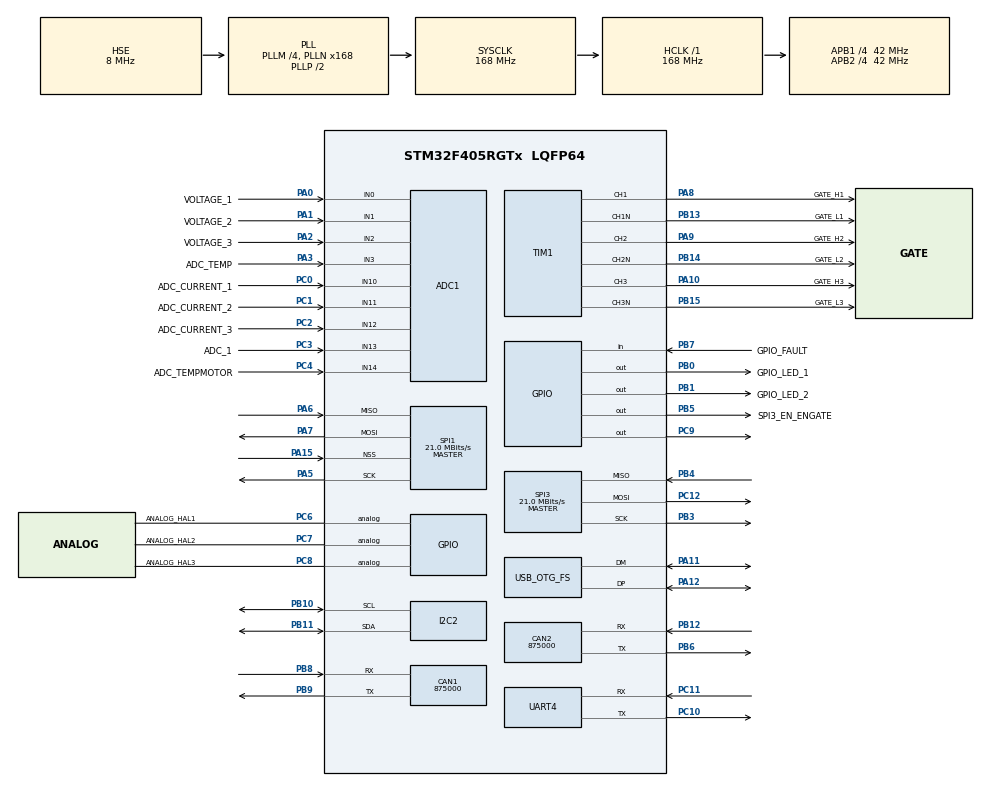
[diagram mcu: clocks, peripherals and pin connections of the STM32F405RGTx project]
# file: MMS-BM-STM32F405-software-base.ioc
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ADC1.Channel-0\#ChannelRegularConversion=ADC_CHANNEL_0
ADC1.NbrOfConversionFlag=1
ADC1.Rank-0\#ChannelRegularConversion=1
ADC1.SamplingTime-0\#ChannelRegularConversion=ADC_SAMPLETIME_3CYCLES
ADC1.master=1
CAN1.BS1=CAN_BS1_1TQ
CAN1.BS2=CAN_BS2_1TQ
CAN1.CalculateBaudRate=875000
CAN1.CalculateTimeBit=1142
CAN1.CalculateTimeQuantum=380.95238095238096
CAN2.BS1=CAN_BS1_1TQ
CAN2.BS2=CAN_BS2_1TQ
CAN2.CalculateBaudRate=875000
CAN2.CalculateTimeBit=1142
CAN2.CalculateTimeQuantum=380.95238095238096
FREERTOS.INCLUDE_vTaskCleanUpResources=1
FREERTOS.Tasks01=defaultTask,24,256,StartDefaultTask,Default,NULL,Dynamic,NULL,NULL
FREERTOS.configENABLE_FPU=1
FREERTOS.configMINIMAL_STACK_SIZE=256
FREERTOS.configQUEUE_REGISTRY_SIZE=32
FREERTOS.configTOTAL_HEAP_SIZE=100000
FREERTOS.configUSE_NEWLIB_REENTRANT=1
Mcu.Family=STM32F4
Mcu.Name=STM32F405RGTx
Mcu.Package=LQFP64
NVIC.OTG_FS_IRQn=true\:5\:0\:false\:false\:true\:true\:false\:true\:true
NVIC.PriorityGroup=NVIC_PRIORITYGROUP_4
NVIC.TIM6_DAC_IRQn=true\:5\:0\:false\:false\:true\:true\:true\:true\:true
NVIC.TIM7_IRQn=true\:15\:0\:false\:false\:true\:false\:false\:true\:true
NVIC.TimeBase=TIM7_IRQn
NVIC.TimeBaseIP=TIM7
PA0-WKUP.GPIO_Label=VOLTAGE_1
PA0-WKUP.Signal=ADCx_IN0
PA1.GPIO_Label=VOLTAGE_2
PA1.Signal=ADCx_IN1
PA10.GPIO_Label=GATE_H3
PA10.Signal=S_TIM1_CH3
PA11.Mode=Device_Only
PA11.Signal=USB_OTG_FS_DM
PA12.Mode=Device_Only
PA12.Signal=USB_OTG_FS_DP
PA13.Mode=Serial_Wire
PA13.Signal=SYS_JTMS-SWDIO
PA14.Mode=Serial_Wire
PA14.Signal=SYS_JTCK-SWCLK
PA15.Mode=NSS_Signal_Hard_Input
PA15.Signal=SPI1_NSS
PA2.GPIO_Label=VOLTAGE_3
PA2.Signal=ADCx_IN2
PA3.GPIO_Label=ADC_TEMP
PA3.Signal=ADCx_IN3
PA5.Mode=Full_Duplex_Master
PA5.Signal=SPI1_SCK
PA6.Mode=Full_Duplex_Master
PA6.Signal=SPI1_MISO
PA7.Mode=Full_Duplex_Master
PA7.Signal=SPI1_MOSI
PA8.GPIO_Label=GATE_H1
PA8.Signal=S_TIM1_CH1
PA9.GPIO_Label=GATE_H2
PA9.Signal=S_TIM1_CH2
PB0.GPIO_Label=GPIO_LED_1
PB0.Signal=GPIO_Output
PB1.GPIO_Label=GPIO_LED_2
PB1.Signal=GPIO_Output
PB10.Mode=I2C
PB10.Signal=I2C2_SCL
PB11.Mode=I2C
PB11.Signal=I2C2_SDA
PB12.Mode=CAN_Activate
PB12.Signal=CAN2_RX
PB13.GPIO_Label=GATE_L1
PB13.Mode=PWM Generation1 CH1 CH1N
PB13.Signal=TIM1_CH1N
PB14.GPIO_Label=GATE_L2
PB14.Mode=PWM Generation2 CH2 CH2N
PB14.Signal=TIM1_CH2N
PB15.GPIO_Label=GATE_L3
PB15.Mode=PWM Generation3 CH3 CH3N
PB15.Signal=TIM1_CH3N
PB3.Mode=Full_Duplex_Master
PB3.Signal=SPI3_SCK
PB4.Mode=Full_Duplex_Master
PB4.Signal=SPI3_MISO
PB5.GPIO_Label=SPI3_EN_ENGATE
PB5.Signal=GPIO_Output
PB6.Mode=CAN_Activate
PB6.Signal=CAN2_TX
PB7.GPIO_Label=GPIO_FAULT
PB7.Signal=GPIO_Input
PB8.Mode=CAN_Activate
PB8.Signal=CAN1_RX
PB9.Mode=CAN_Activate
PB9.Signal=CAN1_TX
PC0.GPIO_Label=ADC_CURRENT_1
PC0.Signal=ADCx_IN10
PC1.GPIO_Label=ADC_CURRENT_2
PC1.Signal=ADCx_IN11
PC10.Mode=Asynchronous
PC10.Signal=UART4_TX
PC11.Mode=Asynchronous
PC11.Signal=UART4_RX
PC12.Mode=Full_Duplex_Master
PC12.Signal=SPI3_MOSI
PC14-OSC32_IN.Mode=LSE-External-Oscillator
PC14-OSC32_IN.Signal=RCC_OSC32_IN
PC15-OSC32_OUT.Mode=LSE-External-Oscillator
PC15-OSC32_OUT.Signal=RCC_OSC32_OUT
PC2.GPIO_Label=ADC_CURRENT_3
PC2.Signal=ADCx_IN12
PC3.GPIO_Label=ADC_1
PC3.Signal=ADCx_IN13
PC4.GPIO_Label=ADC_TEMPMOTOR
PC4.Signal=ADCx_IN14
PC6.GPIO_Label=ANALOG_HAL1
PC6.Signal=GPIO_Analog
PC7.GPIO_Label=ANALOG_HAL2
PC7.Signal=GPIO_Analog
PC8.GPIO_Label=ANALOG_HAL3
PC8.Signal=GPIO_Analog
PC9.Signal=GPIO_Output
PH0-OSC_IN.Mode=HSE-External-Oscillator
PH0-OSC_IN.Signal=RCC_OSC_IN
PH1-OSC_OUT.Mode=HSE-External-Oscillator
PH1-OSC_OUT.Signal=RCC_OSC_OUT
ProjectManager.HeapSize=0x600
ProjectManager.StackSize=0x400
ProjectManager.TargetToolchain=CMake
RCC.48MHZClocksFreq_Value=48000000
RCC.AHBFreq_Value=168000000
RCC.APB1CLKDivider=RCC_HCLK_DIV4
RCC.APB1Freq_Value=42000000
RCC.APB1TimFreq_Value=84000000
RCC.APB2CLKDivider=RCC_HCLK_DIV4
RCC.APB2Freq_Value=42000000
RCC.APB2TimFreq_Value=84000000
RCC.CortexFreq_Value=168000000
RCC.HCLKFreq_Value=168000000
RCC.HSE_VALUE=8000000
RCC.HSI_VALUE=16000000
RCC.PLLM=4
RCC.PLLN=168
RCC.PLLQ=7
RCC.SYSCLKFreq_VALUE=168000000
RCC.SYSCLKSource=RCC_SYSCLKSOURCE_PLLCLK
RCC.VCOOutputFreq_Value=336000000
SH.ADCx_IN0.0=ADC1_IN0,IN0
SH.ADCx_IN1.0=ADC1_IN1,IN1
SH.ADCx_IN10.0=ADC1_IN10,IN10
SH.ADCx_IN11.0=ADC1_IN11,IN11
SH.ADCx_IN12.0=ADC1_IN12,IN12
SH.ADCx_IN13.0=ADC1_IN13,IN13
SH.ADCx_IN14.0=ADC1_IN14,IN14
SH.ADCx_IN2.0=ADC1_IN2,IN2
SH.ADCx_IN3.0=ADC1_IN3,IN3
SH.S_TIM1_CH1.0=TIM1_CH1,PWM Generation1 CH1 CH1N
SH.S_TIM1_CH2.0=TIM1_CH2,PWM Generation2 CH2 CH2N
SH.S_TIM1_CH3.0=TIM1_CH3,PWM Generation3 CH3 CH3N
SPI1.BaudRatePrescaler=SPI_BAUDRATEPRESCALER_2
SPI1.CalculateBaudRate=21.0 MBits/s
SPI1.Direction=SPI_DIRECTION_2LINES
SPI1.Mode=SPI_MODE_MASTER
SPI1.VirtualNSS=VM_NSSHARD
SPI1.VirtualType=VM_MASTER
SPI3.BaudRatePrescaler=SPI_BAUDRATEPRESCALER_2
SPI3.CalculateBaudRate=21.0 MBits/s
SPI3.Direction=SPI_DIRECTION_2LINES
SPI3.Mode=SPI_MODE_MASTER
SPI3.VirtualType=VM_MASTER
TIM1.Channel-PWM\ Generation1\ CH1\ CH1N=TIM_CHANNEL_1
TIM1.Channel-PWM\ Generation2\ CH2\ CH2N=TIM_CHANNEL_2
TIM1.Channel-PWM\ Generation3\ CH3\ CH3N=TIM_CHANNEL_3
TIM6.AutoReloadPreload=TIM_AUTORELOAD_PRELOAD_ENABLE
TIM6.Period=999
TIM6.Prescaler=168
UART4.VirtualMode=Asynchronous
USB_DEVICE.CLASS_NAME_FS=CDC
USB_DEVICE.VirtualMode-CDC_FS=Cdc
USB_DEVICE.VirtualModeFS=Cdc_FS
USB_OTG_FS.VirtualMode=Device_Only
VP_FREERTOS_VS_CMSIS_V2.Mode=CMSIS_V2
VP_RNG_VS_RNG.Mode=RNG_Activate
VP_SYS_VS_tim7.Mode=TIM7
VP_TIM6_VS_ClockSourceINT.Mode=Enable_Timer
VP_USB_DEVICE_VS_USB_DEVICE_CDC_FS.Mode=CDC_FS
board=custom

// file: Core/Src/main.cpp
/* USER CODE BEGIN Header */
/**
  ******************************************************************************
  * @file           : main.c
  * @brief          : Main program body
  ******************************************************************************
  * @attention
  *
  * Copyright (c) 2025 STMicroelectronics.
  * All rights reserved.
  *
  * This software is licensed under terms that can be found in the LICENSE file
  * in the root directory of this software component.
  * If no LICENSE file comes with this software, it is provided AS-IS.
  *
  ******************************************************************************
  */
/* USER CODE END Header */
#include "main.h"
#include "cmsis_os.h"
#include "usb_device.h"

/* USER CODE BEGIN Includes */
#include "main_prog.hpp"

/* USER CODE END Includes */

ADC_HandleTypeDef hadc1;

CAN_HandleTypeDef hcan1;
CAN_HandleTypeDef hcan2;

I2C_HandleTypeDef hi2c2;

RNG_HandleTypeDef hrng;

SPI_HandleTypeDef hspi1;
SPI_HandleTypeDef hspi3;

TIM_HandleTypeDef htim1;
TIM_HandleTypeDef htim6;

UART_HandleTypeDef huart4;

/* Definitions for defaultTask */
osThreadId_t defaultTaskHandle;
const osThreadAttr_t defaultTask_attributes = {
  .name = "defaultTask",
  .stack_size = 256 * 4,
  .priority = (osPriority_t) osPriorityNormal,
};

void SystemClock_Config(void);
static void MX_GPIO_Init(void);
static void MX_ADC1_Init(void);
static void MX_CAN1_Init(void);
static void MX_CAN2_Init(void);
static void MX_I2C2_Init(void);
static void MX_SPI1_Init(void);
static void MX_SPI3_Init(void);
static void MX_TIM1_Init(void);
static void MX_UART4_Init(void);
static void MX_RNG_Init(void);
static void MX_TIM6_Init(void);
void StartDefaultTask(void *argument);

int main(void)
{

  /* MCU Configuration--------------------------------------------------------*/

  /* Reset of all peripherals, Initializes the Flash interface and the Systick. */
  HAL_Init();

  /* Configure the system clock */
  SystemClock_Config();

  /* Initialize all configured peripherals */
  MX_GPIO_Init();
  MX_ADC1_Init();
  MX_CAN1_Init();
  MX_CAN2_Init();
  MX_I2C2_Init();
  MX_SPI1_Init();
  MX_SPI3_Init();
  MX_TIM1_Init();
  MX_UART4_Init();
  MX_RNG_Init();
  MX_TIM6_Init();

  /* Init scheduler */
  osKernelInitialize();
main_prog();

  /* Create the thread(s) */
  /* creation of defaultTask */
  defaultTaskHandle = osThreadNew(StartDefaultTask, NULL, &defaultTask_attributes);

  /* Start scheduler */
  osKernelStart();

  /* We should never get here as control is now taken by the scheduler */

  /* Infinite loop */
  while (1)
  {

  }
}

void SystemClock_Config(void)
{
  RCC_OscInitTypeDef RCC_OscInitStruct = {0};
  RCC_ClkInitTypeDef RCC_ClkInitStruct = {0};

  /** Configure the main internal regulator output voltage
  */
  __HAL_RCC_PWR_CLK_ENABLE();
  __HAL_PWR_VOLTAGESCALING_CONFIG(PWR_REGULATOR_VOLTAGE_SCALE1);

  /** Initializes the RCC Oscillators according to the specified parameters
  * in the RCC_OscInitTypeDef structure.
  */
  RCC_OscInitStruct.OscillatorType = RCC_OSCILLATORTYPE_HSE;
  RCC_OscInitStruct.HSEState = RCC_HSE_ON;
  RCC_OscInitStruct.PLL.PLLState = RCC_PLL_ON;
  RCC_OscInitStruct.PLL.PLLSource = RCC_PLLSOURCE_HSE;
  RCC_OscInitStruct.PLL.PLLM = 4;
  RCC_OscInitStruct.PLL.PLLN = 168;
  RCC_OscInitStruct.PLL.PLLP = RCC_PLLP_DIV2;
  RCC_OscInitStruct.PLL.PLLQ = 7;
  if (HAL_RCC_OscConfig(&RCC_OscInitStruct) != HAL_OK)
  {
    Error_Handler();
  }

  /** Initializes the CPU, AHB and APB buses clocks
  */
  RCC_ClkInitStruct.ClockType = RCC_CLOCKTYPE_HCLK|RCC_CLOCKTYPE_SYSCLK
                              |RCC_CLOCKTYPE_PCLK1|RCC_CLOCKTYPE_PCLK2;
  RCC_ClkInitStruct.SYSCLKSource = RCC_SYSCLKSOURCE_PLLCLK;
  RCC_ClkInitStruct.AHBCLKDivider = RCC_SYSCLK_DIV1;
  RCC_ClkInitStruct.APB1CLKDivider = RCC_HCLK_DIV4;
  RCC_ClkInitStruct.APB2CLKDivider = RCC_HCLK_DIV4;

  if (HAL_RCC_ClockConfig(&RCC_ClkInitStruct, FLASH_LATENCY_5) != HAL_OK)
  {
    Error_Handler();
  }
}

static void MX_ADC1_Init(void)
{

  ADC_ChannelConfTypeDef sConfig = {0};

  /** Configure the global features of the ADC (Clock, Resolution, Data Alignment and number of conversion)
  */
  hadc1.Instance = ADC1;
  hadc1.Init.ClockPrescaler = ADC_CLOCK_SYNC_PCLK_DIV2;
  hadc1.Init.Resolution = ADC_RESOLUTION_12B;
  hadc1.Init.ScanConvMode = DISABLE;
  hadc1.Init.ContinuousConvMode = DISABLE;
  hadc1.Init.DiscontinuousConvMode = DISABLE;
  hadc1.Init.ExternalTrigConvEdge = ADC_EXTERNALTRIGCONVEDGE_NONE;
  hadc1.Init.ExternalTrigConv = ADC_SOFTWARE_START;
  hadc1.Init.DataAlign = ADC_DATAALIGN_RIGHT;
  hadc1.Init.NbrOfConversion = 1;
  hadc1.Init.DMAContinuousRequests = DISABLE;
  hadc1.Init.EOCSelection = ADC_EOC_SINGLE_CONV;
  if (HAL_ADC_Init(&hadc1) != HAL_OK)
  {
    Error_Handler();
  }

  /** Configure for the selected ADC regular channel its corresponding rank in the sequencer and its sample time.
  */
  sConfig.Channel = ADC_CHANNEL_0;
  sConfig.Rank = 1;
  sConfig.SamplingTime = ADC_SAMPLETIME_3CYCLES;
  if (HAL_ADC_ConfigChannel(&hadc1, &sConfig) != HAL_OK)
  {
    Error_Handler();
  }

}

static void MX_CAN1_Init(void)
{

  hcan1.Instance = CAN1;
  hcan1.Init.Prescaler = 16;
  hcan1.Init.Mode = CAN_MODE_NORMAL;
  hcan1.Init.SyncJumpWidth = CAN_SJW_1TQ;
  hcan1.Init.TimeSeg1 = CAN_BS1_1TQ;
  hcan1.Init.TimeSeg2 = CAN_BS2_1TQ;
  hcan1.Init.TimeTriggeredMode = DISABLE;
  hcan1.Init.AutoBusOff = DISABLE;
  hcan1.Init.AutoWakeUp = DISABLE;
  hcan1.Init.AutoRetransmission = DISABLE;
  hcan1.Init.ReceiveFifoLocked = DISABLE;
  hcan1.Init.TransmitFifoPriority = DISABLE;
  if (HAL_CAN_Init(&hcan1) != HAL_OK)
  {
    Error_Handler();
  }

}

static void MX_CAN2_Init(void)
{

  hcan2.Instance = CAN2;
  hcan2.Init.Prescaler = 16;
  hcan2.Init.Mode = CAN_MODE_NORMAL;
  hcan2.Init.SyncJumpWidth = CAN_SJW_1TQ;
  hcan2.Init.TimeSeg1 = CAN_BS1_1TQ;
  hcan2.Init.TimeSeg2 = CAN_BS2_1TQ;
  hcan2.Init.TimeTriggeredMode = DISABLE;
  hcan2.Init.AutoBusOff = DISABLE;
  hcan2.Init.AutoWakeUp = DISABLE;
  hcan2.Init.AutoRetransmission = DISABLE;
  hcan2.Init.ReceiveFifoLocked = DISABLE;
  hcan2.Init.TransmitFifoPriority = DISABLE;
  if (HAL_CAN_Init(&hcan2) != HAL_OK)
  {
    Error_Handler();
  }

}

static void MX_I2C2_Init(void)
{

  hi2c2.Instance = I2C2;
  hi2c2.Init.ClockSpeed = 100000;
  hi2c2.Init.DutyCycle = I2C_DUTYCYCLE_2;
  hi2c2.Init.OwnAddress1 = 0;
  hi2c2.Init.AddressingMode = I2C_ADDRESSINGMODE_7BIT;
  hi2c2.Init.DualAddressMode = I2C_DUALADDRESS_DISABLE;
  hi2c2.Init.OwnAddress2 = 0;
  hi2c2.Init.GeneralCallMode = I2C_GENERALCALL_DISABLE;
  hi2c2.Init.NoStretchMode = I2C_NOSTRETCH_DISABLE;
  if (HAL_I2C_Init(&hi2c2) != HAL_OK)
  {
    Error_Handler();
  }

}

static void MX_RNG_Init(void)
{

  hrng.Instance = RNG;
  if (HAL_RNG_Init(&hrng) != HAL_OK)
  {
    Error_Handler();
  }

}

static void MX_SPI1_Init(void)
{

  /* SPI1 parameter configuration*/
  hspi1.Instance = SPI1;
  hspi1.Init.Mode = SPI_MODE_MASTER;
  hspi1.Init.Direction = SPI_DIRECTION_2LINES;
  hspi1.Init.DataSize = SPI_DATASIZE_8BIT;
  hspi1.Init.CLKPolarity = SPI_POLARITY_LOW;
  hspi1.Init.CLKPhase = SPI_PHASE_1EDGE;
  hspi1.Init.NSS = SPI_NSS_HARD_INPUT;
  hspi1.Init.BaudRatePrescaler = SPI_BAUDRATEPRESCALER_2;
  hspi1.Init.FirstBit = SPI_FIRSTBIT_MSB;
  hspi1.Init.TIMode = SPI_TIMODE_DISABLE;
  hspi1.Init.CRCCalculation = SPI_CRCCALCULATION_DISABLE;
  hspi1.Init.CRCPolynomial = 10;
  if (HAL_SPI_Init(&hspi1) != HAL_OK)
  {
    Error_Handler();
  }

}

static void MX_SPI3_Init(void)
{

  /* SPI3 parameter configuration*/
  hspi3.Instance = SPI3;
  hspi3.Init.Mode = SPI_MODE_MASTER;
  hspi3.Init.Direction = SPI_DIRECTION_2LINES;
  hspi3.Init.DataSize = SPI_DATASIZE_8BIT;
  hspi3.Init.CLKPolarity = SPI_POLARITY_LOW;
  hspi3.Init.CLKPhase = SPI_PHASE_1EDGE;
  hspi3.Init.NSS = SPI_NSS_SOFT;
  hspi3.Init.BaudRatePrescaler = SPI_BAUDRATEPRESCALER_2;
  hspi3.Init.FirstBit = SPI_FIRSTBIT_MSB;
  hspi3.Init.TIMode = SPI_TIMODE_DISABLE;
  hspi3.Init.CRCCalculation = SPI_CRCCALCULATION_DISABLE;
  hspi3.Init.CRCPolynomial = 10;
  if (HAL_SPI_Init(&hspi3) != HAL_OK)
  {
    Error_Handler();
  }

}

static void MX_TIM1_Init(void)
{

  TIM_MasterConfigTypeDef sMasterConfig = {0};
  TIM_OC_InitTypeDef sConfigOC = {0};
  TIM_BreakDeadTimeConfigTypeDef sBreakDeadTimeConfig = {0};

  htim1.Instance = TIM1;
  htim1.Init.Prescaler = 0;
  htim1.Init.CounterMode = TIM_COUNTERMODE_UP;
  htim1.Init.Period = 65535;
  htim1.Init.ClockDivision = TIM_CLOCKDIVISION_DIV1;
  htim1.Init.RepetitionCounter = 0;
  htim1.Init.AutoReloadPreload = TIM_AUTORELOAD_PRELOAD_DISABLE;
  if (HAL_TIM_PWM_Init(&htim1) != HAL_OK)
  {
    Error_Handler();
  }
  sMasterConfig.MasterOutputTrigger = TIM_TRGO_RESET;
  sMasterConfig.MasterSlaveMode = TIM_MASTERSLAVEMODE_DISABLE;
  if (HAL_TIMEx_MasterConfigSynchronization(&htim1, &sMasterConfig) != HAL_OK)
  {
    Error_Handler();
  }
  sConfigOC.OCMode = TIM_OCMODE_PWM1;
  sConfigOC.Pulse = 0;
  sConfigOC.OCPolarity = TIM_OCPOLARITY_HIGH;
  sConfigOC.OCNPolarity = TIM_OCNPOLARITY_HIGH;
  sConfigOC.OCFastMode = TIM_OCFAST_DISABLE;
  sConfigOC.OCIdleState = TIM_OCIDLESTATE_RESET;
  sConfigOC.OCNIdleState = TIM_OCNIDLESTATE_RESET;
  if (HAL_TIM_PWM_ConfigChannel(&htim1, &sConfigOC, TIM_CHANNEL_1) != HAL_OK)
  {
    Error_Handler();
  }
  if (HAL_TIM_PWM_ConfigChannel(&htim1, &sConfigOC, TIM_CHANNEL_2) != HAL_OK)
  {
    Error_Handler();
  }
  if (HAL_TIM_PWM_ConfigChannel(&htim1, &sConfigOC, TIM_CHANNEL_3) != HAL_OK)
  {
    Error_Handler();
  }
  sBreakDeadTimeConfig.OffStateRunMode = TIM_OSSR_DISABLE;
  sBreakDeadTimeConfig.OffStateIDLEMode = TIM_OSSI_DISABLE;
  sBreakDeadTimeConfig.LockLevel = TIM_LOCKLEVEL_OFF;
  sBreakDeadTimeConfig.DeadTime = 0;
  sBreakDeadTimeConfig.BreakState = TIM_BREAK_DISABLE;
  sBreakDeadTimeConfig.BreakPolarity = TIM_BREAKPOLARITY_HIGH;
  sBreakDeadTimeConfig.AutomaticOutput = TIM_AUTOMATICOUTPUT_DISABLE;
  if (HAL_TIMEx_ConfigBreakDeadTime(&htim1, &sBreakDeadTimeConfig) != HAL_OK)
  {
    Error_Handler();
  }
  HAL_TIM_MspPostInit(&htim1);

}

static void MX_TIM6_Init(void)
{

  TIM_MasterConfigTypeDef sMasterConfig = {0};

  htim6.Instance = TIM6;
  htim6.Init.Prescaler = 168;
  htim6.Init.CounterMode = TIM_COUNTERMODE_UP;
  htim6.Init.Period = 999;
  htim6.Init.AutoReloadPreload = TIM_AUTORELOAD_PRELOAD_ENABLE;
  if (HAL_TIM_Base_Init(&htim6) != HAL_OK)
  {
    Error_Handler();
  }
  sMasterConfig.MasterOutputTrigger = TIM_TRGO_RESET;
  sMasterConfig.MasterSlaveMode = TIM_MASTERSLAVEMODE_DISABLE;
  if (HAL_TIMEx_MasterConfigSynchronization(&htim6, &sMasterConfig) != HAL_OK)
  {
    Error_Handler();
  }

}

static void MX_UART4_Init(void)
{

  huart4.Instance = UART4;
  huart4.Init.BaudRate = 115200;
  huart4.Init.WordLength = UART_WORDLENGTH_8B;
  huart4.Init.StopBits = UART_STOPBITS_1;
  huart4.Init.Parity = UART_PARITY_NONE;
  huart4.Init.Mode = UART_MODE_TX_RX;
  huart4.Init.HwFlowCtl = UART_HWCONTROL_NONE;
  huart4.Init.OverSampling = UART_OVERSAMPLING_16;
  if (HAL_UART_Init(&huart4) != HAL_OK)
  {
    Error_Handler();
  }

}

static void MX_GPIO_Init(void)
{
  GPIO_InitTypeDef GPIO_InitStruct = {0};

  /* GPIO Ports Clock Enable */
  __HAL_RCC_GPIOC_CLK_ENABLE();
  __HAL_RCC_GPIOH_CLK_ENABLE();
  __HAL_RCC_GPIOA_CLK_ENABLE();
  __HAL_RCC_GPIOB_CLK_ENABLE();

  /*Configure GPIO pin Output Level */
  HAL_GPIO_WritePin(GPIOB, GPIO_LED_1_Pin|GPIO_LED_2_Pin|SPI3_EN_ENGATE_Pin, GPIO_PIN_RESET);

  /*Configure GPIO pin Output Level */
  HAL_GPIO_WritePin(GPIOC, GPIO_PIN_9, GPIO_PIN_RESET);

  /*Configure GPIO pins : GPIO_LED_1_Pin GPIO_LED_2_Pin SPI3_EN_ENGATE_Pin */
  GPIO_InitStruct.Pin = GPIO_LED_1_Pin|GPIO_LED_2_Pin|SPI3_EN_ENGATE_Pin;
  GPIO_InitStruct.Mode = GPIO_MODE_OUTPUT_PP;
  GPIO_InitStruct.Pull = GPIO_NOPULL;
  GPIO_InitStruct.Speed = GPIO_SPEED_FREQ_LOW;
  HAL_GPIO_Init(GPIOB, &GPIO_InitStruct);

  /*Configure GPIO pins : ANALOG_HAL1_Pin ANALOG_HAL2_Pin ANALOG_HAL3_Pin */
  GPIO_InitStruct.Pin = ANALOG_HAL1_Pin|ANALOG_HAL2_Pin|ANALOG_HAL3_Pin;
  GPIO_InitStruct.Mode = GPIO_MODE_ANALOG;
  GPIO_InitStruct.Pull = GPIO_NOPULL;
  HAL_GPIO_Init(GPIOC, &GPIO_InitStruct);

  /*Configure GPIO pin : PC9 */
  GPIO_InitStruct.Pin = GPIO_PIN_9;
  GPIO_InitStruct.Mode = GPIO_MODE_OUTPUT_PP;
  GPIO_InitStruct.Pull = GPIO_NOPULL;
  GPIO_InitStruct.Speed = GPIO_SPEED_FREQ_LOW;
  HAL_GPIO_Init(GPIOC, &GPIO_InitStruct);

  /*Configure GPIO pin : GPIO_FAULT_Pin */
  GPIO_InitStruct.Pin = GPIO_FAULT_Pin;
  GPIO_InitStruct.Mode = GPIO_MODE_INPUT;
  GPIO_InitStruct.Pull = GPIO_NOPULL;
  HAL_GPIO_Init(GPIO_FAULT_GPIO_Port, &GPIO_InitStruct);

}

void StartDefaultTask(void *argument)
{
  /* init code for USB_DEVICE */
  MX_USB_DEVICE_Init();
  for(;;)
  {
    osDelay(1);
  }
}

void Error_Handler(void)
{
  __disable_irq();
  while (1)
  {
  }
}
